# CY8C5667LTI_LP009 register map
File version: 0.1
Registers are 8-bit, read-write, no defined reset value unless marked. A register's access mark holds for its fields unless they carry their own. Offsets are from the block's base; [hi:lo] are bit positions.

## Droop_Filter
Base 0x4000C784
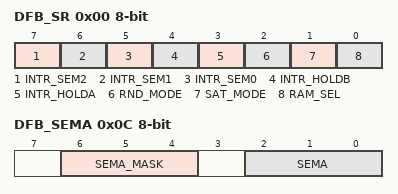
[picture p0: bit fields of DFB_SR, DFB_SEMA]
0x00 DFB_SR — This register contains 5 bits indicating the status of block generated interrupts and 3 bits of status from the Datapath unit. Of the 5 sources of interrupts, only those configured in INT_CTRL are activated. If not activated in INT_CTRL they will never assert in this register. If an interrupt source bit (7:3) is set this indicates it is at least one of the sources of the currently driven interrupt on dfb_intr. More than one of the 5 could be asserted. Note that if the system SW wishes to poll for an event and not have an interrupt generated, the interrupt must be enabled in the INT_CTRL register so that it can be polled here and then disable the interrupt in the Interrupt Controller or not connect the dfb_intr signal to the Interrupt Controller at all by not configuring the DSI path. Bits 2:0 are read-only - writes to these bits have no effect. Writes to bits 7:3 of '1' clear the bit, writes of 0 have no effect.
  [7] INTR_SEM2 ro — If this bit is high, semaphore register bit 2 is a source of the current interrupt. Write a '1' to this bit to clear it.
  [6] INTR_SEM1 ro — If this bit is high, semaphore register bit 1 is a source of the current interrupt. Write a '1' to this bit to clear it.
  [5] INTR_SEM0 ro — If this bit is high, semaphore register bit 0 is a source of the current interrupt. Write a '1' to this bit to clear it.
  [4] INTR_HOLDB ro — If this bit is high, Holding register B is a source of the current interrupt. Write a '1' to this bit to clear it. Reading the Holding register B also clears this bit.
  [3] INTR_HOLDA ro — f this bit is high, Holding register A is a source of the current interrupt. Write a '1' to this bit to clear it. Reading the Holding register A also clears this bit.
  [2] RND_MODE ro — Indicates that the DP is in Round mode - meaning that any result passing out of the DP unit is being rounded to a 16-bit value.
  [1] SAT_MODE ro — Indicates that the DP unit is in Saturation mode - meaning that any mathematic operation executed that produces a number outside the range of a 24-bit 2's compliment number is clamped to the mode positive or negative number allowed. Saturation mode is set/unset under Assembly control in the DFB Controller.
  [0] RAM_SEL ro — This bit indicates which Control Store memory is in use, RAM A or RAM B.
0x0C DFB_SEMA — This register controls the DFB Semaphore register. These bits are used to pass semaphores between the DFB Controller and the System SW. Their use and purpose is user defined. A read to this register returns what was last written by either System SW or the DFB Controller.
  [6:4] SEMA_MASK wo — These bits are used to mask writes to bits 2-0. They are write-only. If bit 4 is a 1 then the value on bit 0 will be written to SEM0, otherwise SEM0 will not be altered. Likewise for MASK1 and SEM1, and MASK2 and SEM2.
  [2:0] SEMA — These bits are used to pass semaphores between the DFB Controller and the System SW. Their definition is user defined. There is no HW implementing an arbitration methodology should both the System and Control access the same SEM bit at the same time. Coherency of the SEM bits is the responsibility of the SW running on the Controller and the System CPU. If the same SEM bit is written by the Controller and the System in the exact same cycle (a collision), the System write takes precedence over the Controller. In this manner, each of the 3 bits are treated individually.
0x1C DFB_STAGEA — This is the low byte of the Streaming input Staging Register - Port A. If the Staging A Data Alignment bit is set in the DALIGN register then data written to this address will be written into bits 15:8 instead. Although the Staging A/B registers are shown here as 3 byte-wide registers, it is primarily intended that they be treated as 24-bit registers at a 32-bit offset. Due to the architecture of the DFB, any value written to the Staging A or B registers that is less than 24 bits in size must be msb aligned. For example, a 16-bit value written to the Staging A register must be written to STAGExM and STAGExH with STAGEx set to 0. The Staging registers support byte and half-word accesses as well. However, if byte and half-word accesses are used then the Key Coherency Byte feature must be used. Also see the COHER register description below. In some use models it is desirous to write 16-bit values on bus bits 15:0 and have them actually writing to bits 23:8 of the register. A System SW convenience feature to accomplish this is provided. If the Data Alignment bit for these registers is set in the DALIGN register the byte written is shifted up (left) to the next byte position. This is only true of the two lower bytes. READ: AHB: What was last written. The DFB Controller reads this register (and the other 2 bytes) by asserting busrd and setting the low-order ACU RAM address bit low. WRITE: Writes the low byte of the input Staging Register for Port A or the middle byte if the Data Alignment bit is set in the DALIGN register.
  [7:0] STGA_LOW — A write to this register sets the low byte of the input Staging Register for Port A.
0x1D DFB_STAGEAM — This is the middle byte of the Streaming input Staging Register - Port A. If the Staging A Data Alignment bit is set in the DALIGN register then data written to this address will be written into bits 23:16 instead. See usage notes in STAGEA register description.
  [7:0] STGA_MID — A write to this register sets the middle byte of the input Staging Register for Port A.
0x1E DFB_STAGEAH — This is the high byte of the Streaming input Staging Register - Port A. See usage notes in STAGEA register description.
  [7:0] STGA_HIGH — A write to this register sets the high byte of the input Staging Register for Port A.
0x20 DFB_STAGEB — This is the low byte of the Streaming input Staging Register - Port B. If the Staging B Data Alignment bit is set in the DALIGN register then data written to this address will be written into bits 15:8 instead. See usage notes in STAGEA register description.
  [7:0] STGB_LOW — A write to this register sets the low byte of the input Staging Register for Port B.
0x21 DFB_STAGEBM — This is the middle byte of the Streaming input Staging Register - Port B. If the Staging B Data Alignment bit is set in the DALIGN register then data written to this address will be written into bits 23:16 instead. See usage notes in STAGEA register description.
  [7:0] STGB_MID — A write to this register sets the middle byte of the input Staging Register for Port B.
0x22 DFB_STAGEBH — This is the high byte of the Streaming input Staging Register - Port B. See usage notes in STAGEA register description.
  [7:0] STGA_HIGH — A write to this register sets the high byte of the input Staging Register for Port B.
0x24 DFB_HOLDA — This is the low byte of the output Holding Register - Port A. If the Holding A Data Alignment bit is set in the DALIGN register then data read from this address will be bits 15:8 instead. Although the Holding A/B registers are shown here as 3 byte-wide registers, it is primarily intended that they be treated as 24-bit registers at a 32-bit offset. Due to the architecture of the DFB, any value read from the Holding A or B registers will be msb aligned unless shifted otherwise by the Datapath shifter. For example, if the resultant output samples are 16-bit values, a read of a Holding register will produce that data on bits 23:8, or HOLDxH and HOLDxM. The Holding registers support byte and half-word accesses as well. However, if byte and half-word accesses are used then the Key Coherency Byte feature must be used. Also see the COHER register description below. In some use models it is desirous to read 16-bit values on bus bits 15:0 and have them actually source from bits 23:8 of the register. A System SW convenience feature to accomplish this is provided. If the Data Alignment bit for these registers is set in the DALIGN register the byte read is shifted down (right) to the next byte position. This is only true of the two upper bytes. Also as a System SW convenience, reads of the Holding registers are sign extended up to bit 31 of the bus even though the top byte is not documented or implemented as a real register. If the DFB is configured (see INT_CTRL) to generate an interrupt based on valid data in the Holding register, the interrupt status bit in the SR register will be cleared when any portion (byte, 16-bit or full 32-bit read) of the Holding register is read, by the CPU or the DMA Controller. READ: What was last written by the DFB Controller. WRITE: Read-only by AHB, DFB Controller writes to this register (including the other 2 bytes) with a buswr command and the low-order ACU RAM address bit set low.
  [7:0] HOLDA_LOW ro — Low byte of the output Holding Register, Port A.
0x25 DFB_HOLDAM — This is the middle byte of the output Holding Register - Port A. If the Holding A Data Alignment bit is set in the DALIGN register then data read from this address will be bits 23:16 instead. See usage notes in HOLDA register description.
  [7:0] HOLDA_MID ro — Middle byte of the output Holding Register, Port A.
0x26 DFB_HOLDAH — This is the high byte of the output Holding Register - Port A. See usage notes in HOLDA register description.
  [7:0] HOLDA_HIGH ro — High byte of the output Holding Register, Port A.
0x28 DFB_HOLDB — This is the middle byte of the output Holding Register - Port B. If the Holding B Data Alignment bit is set in the DALIGN register then data read from this address will be bits 23:16 instead. See usage notes in HOLDA register description.
  [7:0] HOLDB_LOW ro — Low byte of the output Holding Register, Port B.
0x29 DFB_HOLDBM — This is the middle byte of the output Holding Register - Port B. If the Holding A Data Alignment bit is set in the DALIGN register then data read from this address will be bits 23:16 instead. See usage notes in HOLDA register description.
  [7:0] HOLDB_MID ro — Middle byte of the output Holding Register, Port B.
0x2A DFB_HOLDBH — This is the high byte of the output Holding Register - Port B. See usage notes in HOLDA register description.
  [7:0] HOLDB_HIGH ro — High byte of the output Holding Register, Port B.

## I2S
Base 0x4000656B
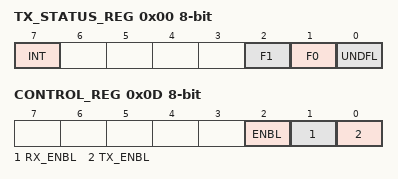
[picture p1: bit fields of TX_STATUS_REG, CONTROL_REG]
0x00 TX_STATUS_REG
  [7] INT ro — Interrupt bit
  [2] F1 ro — FIFO 1 state
    0=FULL; 1=NOT_FULL
  [1] F0 ro — FIFO 0 state
    0=FULL; 1=NOT_FULL
  [0] UNDFL ro — FIFO Underflow Error
    0=NO_UNDERFLOW; 1=UNDERFLOW
0x0D CONTROL_REG
  [all] fields
    1=ENABLED; 0=DISABLED
  [2] ENBL — Starts the generation of the WS and SCK outputs
  [1] RX_ENBL — Enables Rx direction. This bit is applicable only if Rx direction presents for the component
  [0] TX_ENBL — Enables Tx direction. This bit is applicable only if Tx direction presents for the component

## I2C_Master
Base 0x400049C8
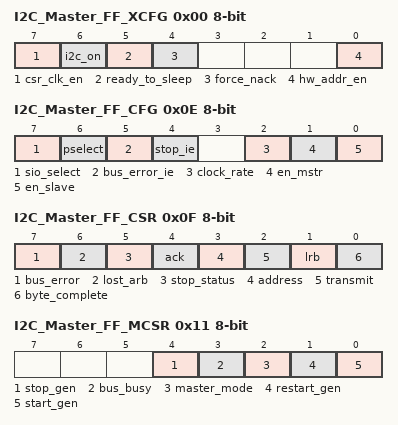
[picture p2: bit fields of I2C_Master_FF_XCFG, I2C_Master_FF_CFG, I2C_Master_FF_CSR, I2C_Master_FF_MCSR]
0x00 I2C_Master_FF_XCFG — Extended Configuration Register: I2C_XCFG
  [7] csr_clk_en, [6] i2c_on, [5] ready_to_sleep ro, [4] force_nack, [0] hw_addr_en
0x02 I2C_Master_FF_ADDR — Slave Adddress Register: I2C_ADR
  [6:0] slave_address — This register holds the slave's 7-bit address.
0x0E I2C_Master_FF_CFG — Configuration Register: I2C_CFG
  [7] sio_select, [6] pselect, [5] bus_error_ie, [4] stop_ie, [2] clock_rate, [1] en_mstr, [0] en_slave
0x0F I2C_Master_FF_CSR — Control and Status Register: I2C_CSR
  [7] bus_error, [6] lost_arb, [5] stop_status, [4] ack, [3] address, [2] transmit, [1] lrb, [0] byte_complete
0x10 I2C_Master_FF_DATA — Data Register: I2C_D
  [7:0] data — This register provides read/write access to the Shift register.
0x11 I2C_Master_FF_MCSR — Master Control and Status Register: I2C_MCSR
  [4] stop_gen, [3] bus_busy ro, [2] master_mode ro, [1] restart_gen, [0] start_gen
0x13 I2C_Master_FF__CLK_DIV1 — Divider of BUS_CLK low part: I2C_CLK_DIV1
  [7:0] Div
0x14 I2C_Master_FF__CLK_DIV2 — Divider high part: I2C_CLK_DIV1
  [1:0] Div
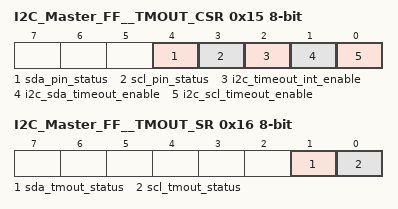
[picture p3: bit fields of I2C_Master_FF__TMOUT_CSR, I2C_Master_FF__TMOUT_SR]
0x15 I2C_Master_FF__TMOUT_CSR — Extended Configuration Register: I2C_TMOUT_CSR
  [4] sda_pin_status, [3] scl_pin_status, [2] i2c_timeout_int_enable ro, [1] i2c_sda_timeout_enable, [0] i2c_scl_timeout_enable
0x16 I2C_Master_FF__TMOUT_SR — Extended Configuration Register: I2C_TMOUT_SR
  [1] sda_tmout_status, [0] scl_tmout_status
0x17 I2C_Master_FF__TMOUT_CFG0 — Extended Configuration Register: TMOUT_CFG0
  [7:0] timeout_period_lowbyte
0x18 I2C_Master_FF__TMOUT_CFG1 — Extended Configuration Register: TMOUT_CFG1
  [3:0] timeout_period_highnibble
